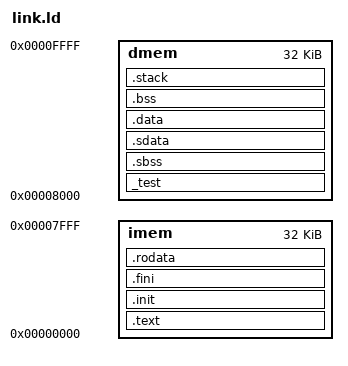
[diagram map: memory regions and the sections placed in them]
OUTPUT_ARCH( "riscv" )

_STACK_SIZE = DEFINED(_STACK_SIZE) ? _STACK_SIZE : 0x1000;
_TEST_SIZE = DEFINED(_TEST_SIZE) ? _TEST_SIZE : 0x100;

/*****************************************************************************
 * Define memory layout
 ****************************************************************************/
MEMORY {
  imem : ORIGIN = 0x00000000, LENGTH = 0x00008000
  dmem : ORIGIN = 0x00008000, LENGTH = 0x00008000
}

/* Specify the default entry point to the program */

ENTRY(_start)

/*****************************************************************************
 * Define the sections, and where they are mapped in memory 
 ****************************************************************************/
SECTIONS {
  .text : {
    setup.o(.text);
    *(.text);
    *(.text.*);
  } > imem

  .init : {
    KEEP (*(.init))
  } > imem

  .fini : {
    KEEP (*(.fini))
  } > imem

  .rodata : {
    __rodata_start = .;
    *(.rodata)
    *(.rodata.*)
    *(.gnu.linkonce.r.*)
    __rodata_end = .;
  } > imem

  _test : {
    . = ALIGN(4);
    _test_start = .;
    . += _TEST_SIZE;
    _test_end = .;
  } > dmem

  .sbss : {
    __sbss_start = .;
    *(.sbss)
    *(.sbss.*)
    *(.gnu.linkonce.sb.*)
    __sbss_end = .;
  } > dmem

  .sdata : {
    _gp = . + 0x800;
    *(.srodata.cst16) *(.srodata.cst8) *(.srodata.cst4) *(.srodata.cst2) *(.srodata*)
    *(.sdata .sdata.* .gnu.linkonce.s.*)
  } > dmem

  .data : {
    . = ALIGN(4);
    __data_start = .;
    *(.data)
    *(.data.*)
    *(.gnu.linkonce.d.*)
    __data_end = .;
  } > dmem

  .bss : {
    . = ALIGN(4);
    __bss_start = .;
    *(.bss)
    *(.bss.*)
    *(.gnu.linkonce.b.*)
    *(COMMON)
    . = ALIGN(4);
    __bss_end = .;
  } > dmem

  .stack : {
    . = ALIGN(4);
    _stack_end = .;
    . += _STACK_SIZE;
    _stack = .;
    __stack = _stack;
  } > dmem

  . = ORIGIN(dmem) + LENGTH(dmem) - 4;
  _sim_end = .;
  . += 4;
  _end = .;
}
